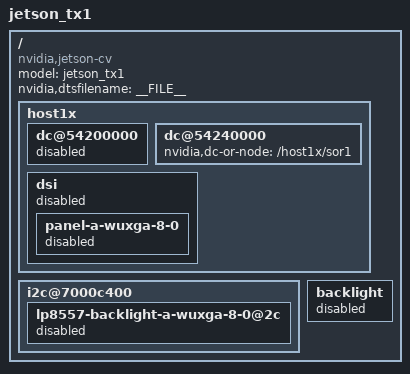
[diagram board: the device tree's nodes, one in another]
/*
 * arch/arm64/boot/dts/tegra210-jetson-tx1-p2597-2180-a01-devkit.dts
 *
 * Copyright (c) 2014-2015, NVIDIA CORPORATION.  All rights reserved.
 *
 * This program is free software; you can redistribute it and/or modify
 * it under the terms of the GNU General Public License as published by
 * the Free Software Foundation; version 2 of the License.
 *
 * This program is distributed in the hope that it will be useful, but WITHOUT
 * ANY WARRANTY; without even the implied warranty of MERCHANTABILITY or
 * FITNESS FOR A PARTICULAR PURPOSE.  See the GNU General Public License for
 * more details.
 *
 */

#include "tegra210-jetson-cv-base-p2597-2180-a00.dts"

/ {
	model = "jetson_tx1";
	compatible = "nvidia,jetson-cv", "nvidia,tegra210";
	nvidia,dtsfilename = __FILE__;

	#address-cells = <2>;
	#size-cells = <2>;

	host1x {
		dc@54200000 {
			status = "disabled";
		};

		dc@54240000 {
			nvidia,dc-or-node = "/host1x/sor1";
		};

		dsi {
			status = "disabled";
			panel-a-wuxga-8-0 {
				status = "disabled";
			};
		};
	};

	i2c@7000c400 {
		lp8557-backlight-a-wuxga-8-0@2c {
			status = "disabled";
		};
	};

	backlight {
		status = "disabled";
	};
};
